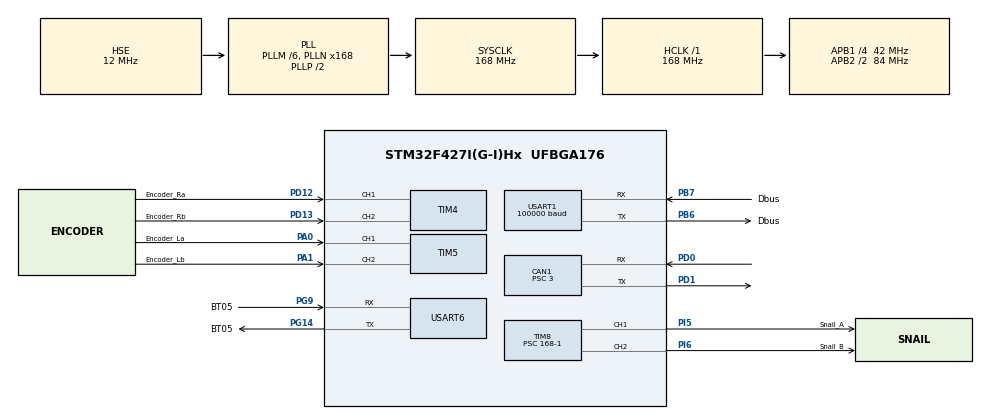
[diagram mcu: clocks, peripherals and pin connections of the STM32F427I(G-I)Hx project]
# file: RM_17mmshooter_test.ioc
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CAN1.BS1=CAN_BS1_10TQ
CAN1.BS2=CAN_BS2_3TQ
CAN1.CalculateBaudRate=1000000
CAN1.CalculateTimeBit=999.99
CAN1.CalculateTimeQuantum=71.42857142857143
CAN1.Prescaler=3
Dma.Request0=USART1_RX
Dma.Request1=USART6_RX
Dma.USART1_RX.0.Direction=DMA_PERIPH_TO_MEMORY
Dma.USART1_RX.0.FIFOMode=DMA_FIFOMODE_DISABLE
Dma.USART1_RX.0.Instance=DMA2_Stream2
Dma.USART1_RX.0.MemDataAlignment=DMA_MDATAALIGN_BYTE
Dma.USART1_RX.0.MemInc=DMA_MINC_ENABLE
Dma.USART1_RX.0.Mode=DMA_CIRCULAR
Dma.USART1_RX.0.PeriphDataAlignment=DMA_PDATAALIGN_BYTE
Dma.USART1_RX.0.PeriphInc=DMA_PINC_DISABLE
Dma.USART1_RX.0.Priority=DMA_PRIORITY_LOW
Dma.USART6_RX.1.Direction=DMA_PERIPH_TO_MEMORY
Dma.USART6_RX.1.FIFOMode=DMA_FIFOMODE_DISABLE
Dma.USART6_RX.1.Instance=DMA2_Stream1
Dma.USART6_RX.1.MemDataAlignment=DMA_MDATAALIGN_BYTE
Dma.USART6_RX.1.MemInc=DMA_MINC_ENABLE
Dma.USART6_RX.1.Mode=DMA_CIRCULAR
Dma.USART6_RX.1.PeriphDataAlignment=DMA_PDATAALIGN_BYTE
Dma.USART6_RX.1.PeriphInc=DMA_PINC_DISABLE
Dma.USART6_RX.1.Priority=DMA_PRIORITY_LOW
Mcu.Family=STM32F4
Mcu.Name=STM32F427I(G-I)Hx
Mcu.Package=UFBGA176
NVIC.CAN1_RX0_IRQn=true\:0\:0\:false\:false\:true\:true\:true
NVIC.DMA2_Stream1_IRQn=true\:0\:0\:false\:false\:true\:false\:true
NVIC.DMA2_Stream2_IRQn=true\:0\:0\:false\:false\:true\:false\:true
NVIC.PriorityGroup=NVIC_PRIORITYGROUP_4
NVIC.TIM2_IRQn=true\:0\:0\:false\:false\:true\:true\:true
NVIC.TIM3_IRQn=true\:0\:0\:false\:false\:true\:true\:true
NVIC.USART1_IRQn=true\:0\:0\:false\:false\:true\:true\:true
NVIC.USART6_IRQn=true\:0\:0\:false\:false\:true\:true\:true
PA0/WKUP.GPIO_Label=Encoder_La
PA0/WKUP.Signal=S_TIM5_CH1
PA1.GPIO_Label=Encoder_Lb
PA1.Signal=S_TIM5_CH2
PA13.Mode=Trace_Asynchronous_SW
PA13.Signal=SYS_JTMS-SWDIO
PA14.Mode=Trace_Asynchronous_SW
PA14.Signal=SYS_JTCK-SWCLK
PB3.Mode=Trace_Asynchronous_SW
PB3.Signal=SYS_JTDO-SWO
PB6.GPIO_Label=Dbus
PB6.Mode=Asynchronous
PB6.Signal=USART1_TX
PB7.GPIO_Label=Dbus
PB7.Mode=Asynchronous
PB7.Signal=USART1_RX
PD0.Mode=CAN_Activate
PD0.Signal=CAN1_RX
PD1.Mode=CAN_Activate
PD1.Signal=CAN1_TX
PD12.GPIO_Label=Encoder_Ra
PD12.Signal=S_TIM4_CH1
PD13.GPIO_Label=Encoder_Rb
PD13.Signal=S_TIM4_CH2
PG14.GPIO_Label=BT05
PG14.Mode=Asynchronous
PG14.Signal=USART6_TX
PG9.GPIO_Label=BT05
PG9.Mode=Asynchronous
PG9.Signal=USART6_RX
PH0/OSC_IN.Mode=HSE-External-Oscillator
PH0/OSC_IN.Signal=RCC_OSC_IN
PH1/OSC_OUT.Mode=HSE-External-Oscillator
PH1/OSC_OUT.Signal=RCC_OSC_OUT
PI5.GPIO_Label=Snail_A
PI5.Signal=S_TIM8_CH1
PI6.GPIO_Label=Snail_B
PI6.Signal=S_TIM8_CH2
ProjectManager.HeapSize=0x200
ProjectManager.StackSize=0x400
ProjectManager.TargetToolchain=MDK-ARM V5
RCC.48MHZClocksFreq_Value=84000000
RCC.AHBFreq_Value=168000000
RCC.APB1CLKDivider=RCC_HCLK_DIV4
RCC.APB1Freq_Value=42000000
RCC.APB1TimFreq_Value=84000000
RCC.APB2CLKDivider=RCC_HCLK_DIV2
RCC.APB2Freq_Value=84000000
RCC.APB2TimFreq_Value=168000000
RCC.CortexFreq_Value=168000000
RCC.HCLKFreq_Value=168000000
RCC.HSE_VALUE=12000000
RCC.HSI_VALUE=16000000
RCC.LSE_VALUE=32768
RCC.PLLM=6
RCC.PLLN=168
RCC.PLLSourceVirtual=RCC_PLLSOURCE_HSE
RCC.SYSCLKFreq_VALUE=168000000
RCC.SYSCLKSource=RCC_SYSCLKSOURCE_PLLCLK
RCC.VCOOutputFreq_Value=336000000
SH.S_TIM4_CH1.0=TIM4_CH1,Encoder_Interface
SH.S_TIM4_CH2.0=TIM4_CH2,Encoder_Interface
SH.S_TIM5_CH1.0=TIM5_CH1,Encoder_Interface
SH.S_TIM5_CH2.0=TIM5_CH2,Encoder_Interface
SH.S_TIM8_CH1.0=TIM8_CH1,PWM Generation1 CH1
SH.S_TIM8_CH2.0=TIM8_CH2,PWM Generation2 CH2
TIM2.Period=5000-1
TIM2.Prescaler=84-1
TIM3.Period=2000-1
TIM3.Prescaler=84-1
TIM4.EncoderMode=TIM_ENCODERMODE_TI12
TIM4.IC1Filter=0
TIM4.IC2Filter=0
TIM5.EncoderMode=TIM_ENCODERMODE_TI12
TIM5.IC1Filter=0
TIM5.IC2Filter=0
TIM8.Channel-PWM\ Generation1\ CH1=TIM_CHANNEL_1
TIM8.Channel-PWM\ Generation2\ CH2=TIM_CHANNEL_2
TIM8.Period=2000-1
TIM8.Prescaler=168-1
USART1.BaudRate=100000
USART1.Mode=MODE_RX
USART1.Parity=PARITY_EVEN
USART1.VirtualMode=VM_ASYNC
USART6.VirtualMode=VM_ASYNC
VP_TIM2_VS_ClockSourceINT.Mode=Internal
VP_TIM3_VS_ClockSourceINT.Mode=Internal
VP_TIM8_VS_ClockSourceINT.Mode=Internal
board=custom

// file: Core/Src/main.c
/* USER CODE BEGIN Header */
/**
  ******************************************************************************
  * @file           : main.c
  * @brief          : Main program body
  ******************************************************************************
  * @attention
  *
  * <h2><center>&copy; Copyright (c) 2021 STMicroelectronics.
  * All rights reserved.</center></h2>
  *
  * This software component is licensed by ST under BSD 3-Clause license,
  * the "License"; You may not use this file except in compliance with the
  * License. You may obtain a copy of the License at:
  *                        opensource.org/licenses/BSD-3-Clause
  *
  ******************************************************************************
  */
/* USER CODE END Header */
#include "main.h"
#include "can.h"
#include "dma.h"
#include "tim.h"
#include "usart.h"
#include "gpio.h"

/* USER CODE BEGIN Includes */
#include "init_config.h"
/* USER CODE END Includes */

void SystemClock_Config(void);

int main(void)
{

  /* MCU Configuration--------------------------------------------------------*/

  /* Reset of all peripherals, Initializes the Flash interface and the Systick. */
  HAL_Init();

  /* Configure the system clock */
  SystemClock_Config();

  /* Initialize all configured peripherals */
  MX_GPIO_Init();
  MX_DMA_Init();
  MX_CAN1_Init();
  MX_USART1_UART_Init();
  MX_TIM2_Init();
  MX_TIM4_Init();
  MX_TIM5_Init();
  MX_TIM8_Init();
  MX_USART6_UART_Init();
  MX_TIM3_Init();
  /* USER CODE BEGIN 2 */
 frameInit();
  /* USER CODE END 2 */

  /* Infinite loop */
  while (1)
  {

    /* USER CODE BEGIN 3 */
	  mainloop();
  }
  /* USER CODE END 3 */
}

void SystemClock_Config(void)
{
  RCC_OscInitTypeDef RCC_OscInitStruct = {0};
  RCC_ClkInitTypeDef RCC_ClkInitStruct = {0};

  /** Configure the main internal regulator output voltage
  */
  __HAL_RCC_PWR_CLK_ENABLE();
  __HAL_PWR_VOLTAGESCALING_CONFIG(PWR_REGULATOR_VOLTAGE_SCALE1);
  /** Initializes the RCC Oscillators according to the specified parameters
  * in the RCC_OscInitTypeDef structure.
  */
  RCC_OscInitStruct.OscillatorType = RCC_OSCILLATORTYPE_HSE;
  RCC_OscInitStruct.HSEState = RCC_HSE_ON;
  RCC_OscInitStruct.PLL.PLLState = RCC_PLL_ON;
  RCC_OscInitStruct.PLL.PLLSource = RCC_PLLSOURCE_HSE;
  RCC_OscInitStruct.PLL.PLLM = 6;
  RCC_OscInitStruct.PLL.PLLN = 168;
  RCC_OscInitStruct.PLL.PLLP = RCC_PLLP_DIV2;
  RCC_OscInitStruct.PLL.PLLQ = 4;
  if (HAL_RCC_OscConfig(&RCC_OscInitStruct) != HAL_OK)
  {
    Error_Handler();
  }
  /** Initializes the CPU, AHB and APB buses clocks
  */
  RCC_ClkInitStruct.ClockType = RCC_CLOCKTYPE_HCLK|RCC_CLOCKTYPE_SYSCLK
                              |RCC_CLOCKTYPE_PCLK1|RCC_CLOCKTYPE_PCLK2;
  RCC_ClkInitStruct.SYSCLKSource = RCC_SYSCLKSOURCE_PLLCLK;
  RCC_ClkInitStruct.AHBCLKDivider = RCC_SYSCLK_DIV1;
  RCC_ClkInitStruct.APB1CLKDivider = RCC_HCLK_DIV4;
  RCC_ClkInitStruct.APB2CLKDivider = RCC_HCLK_DIV2;

  if (HAL_RCC_ClockConfig(&RCC_ClkInitStruct, FLASH_LATENCY_5) != HAL_OK)
  {
    Error_Handler();
  }
}

void Error_Handler(void)
{
}

/************************ (C) COPYRIGHT STMicroelectronics *****END OF FILE****/
